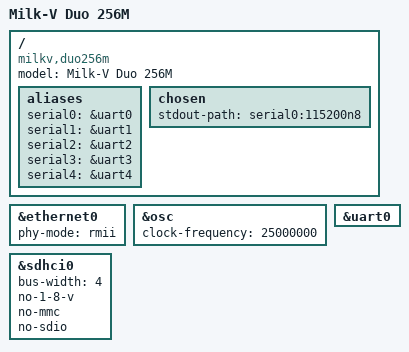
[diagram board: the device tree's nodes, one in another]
// SPDX-License-Identifier: (GPL-2.0 OR MIT)
/*
 * Copyright (C) 2026 Hiago De Franco <hfranco@baylibre.com>
 */

/dts-v1/;

#include "sg2002.dtsi"

/ {
	model = "Milk-V Duo 256M";
	compatible = "milkv,duo256m", "sophgo,sg2002";

	aliases {
		serial0 = &uart0;
		serial1 = &uart1;
		serial2 = &uart2;
		serial3 = &uart3;
		serial4 = &uart4;
	};

	chosen {
		stdout-path = "serial0:115200n8";
	};
};

&ethernet0 {
	status = "okay";
	phy-mode = "rmii";
};

&osc {
	clock-frequency = <25000000>;
};

&sdhci0 {
	status = "okay";
	bus-width = <4>;
	no-1-8-v;
	no-mmc;
	no-sdio;
};

&uart0 {
	status = "okay";
};
